# apollo3p register map
Vendor: Ambiq Micro; Series: Apollo; File version: 1.0
CPU: CM4 r1p0, little endian, MPU, FPU, I-cache, D-cache, VTOR, ITCM, DTCM, 3 interrupt priority bits, 0 interrupts
Registers are 32-bit, read-write, reset 0x0 unless marked. A register's access mark holds for its fields unless they carry their own. Offsets are from the block's base; [hi:lo] are bit positions; {n}, {i} and the like mark numbered series; 'fields as' and 'values as' point back to an identical list.

## ADC — Analog Digital Converter Control
Base 0x50010000
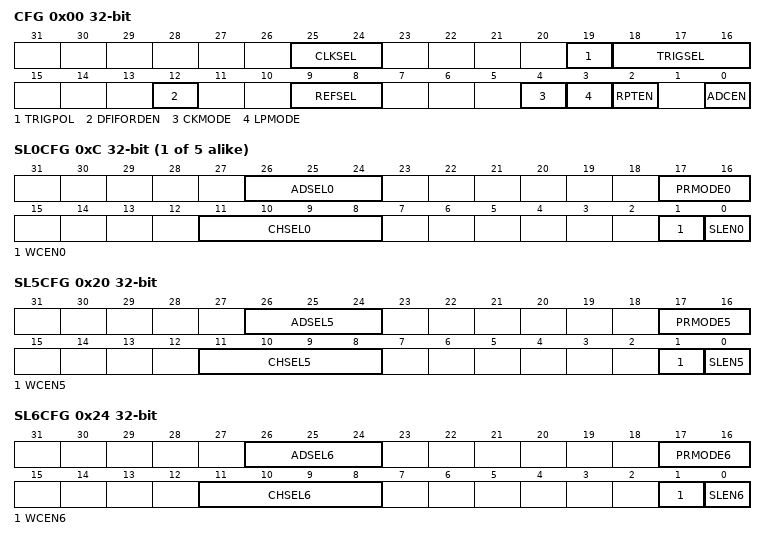
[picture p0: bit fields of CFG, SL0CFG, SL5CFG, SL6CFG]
0x00 CFG — The ADC Configuration Register contains the software control for selecting the clock frequency used for the SAR conversions, the trigger polarity, the trigger select, the reference voltage select, the low power mode, the operating mode (single scan per trigger vs. repeating mode) and ADC enable.
  [25:24] CLKSEL — Select the source and frequency for the ADC clock. All values not enumerated below are undefined.
    0=OFF (Off mode. The HFRC or HFRC_DIV2 clock must be selected for the ADC to function. The ADC controller automatically shuts off the clock in it's low power modes. When setting ADCEN to '0', the CLKSEL should remain set to one of the two clock selects for proper power down sequencing.); 1=HFRC (HFRC Core Clock divided by (CORESEL+1)); 2=HFRC_DIV2 (HFRC Core Clock / 2 further divided by (CORESEL+1))
  [19] TRIGPOL — This bit selects the ADC trigger polarity for external off chip triggers.
    0=RISING_EDGE (Trigger on rising edge.); 1=FALLING_EDGE (Trigger on falling edge.)
  [18:16] TRIGSEL — Select the ADC trigger source.
    {v}=EXT{v} (Off chip External Trigger{v} (ADC_ET{v})) (v=0..3); 4=VCOMP (Voltage Comparator Output); 7=SWT (Software Trigger)
  [12] DFIFORDEN — Destructive FIFO Read Enable. Setting this will enable FIFO pop upon reading the FIFOPR register.
    0=DIS (Destructive Reads are prevented. Reads to the FIFOPR register will not POP an entry off the FIFO.); 1=EN (Reads to the FIFOPR register will automatically pop an entry off the FIFO.)
  [9:8] REFSEL — Select the ADC reference voltage.
    0=INT2P0 (Internal 2.0V Bandgap Reference Voltage); 1=INT1P5 (Internal 1.5V Bandgap Reference Voltage); 2=EXT2P0 (Off Chip 2.0V Reference); 3=EXT1P5 (Off Chip 1.5V Reference)
  [4] CKMODE — Clock mode register
    0=LPCKMODE (Disable the clock between scans for LPMODE0. Set LPCKMODE to 0x1 while configuring the ADC.); 1=LLCKMODE (Low Latency Clock Mode. When set, HFRC and the adc_clk will remain on while in functioning in LPMODE0.)
  [3] LPMODE — Select power mode to enter between active scans.
    0=MODE0 (Low Power Mode 0. Leaves the ADC fully powered between scans with minimum latency between a trigger event and sample data collection.); 1=MODE1 (Low Power Mode 1. Powers down all circuity and clocks associated with the ADC until the next trigger event. Between scans, the reference buffer requires up to 50us of delay from a scan trigger event before the conversion will commence while operating in this mode.)
  [2] RPTEN — This bit enables Repeating Scan Mode.
    0=SINGLE_SCAN (In Single Scan Mode, the ADC will complete a single scan upon each trigger event.); 1=REPEATING_SCAN (In Repeating Scan Mode, the ADC will complete it's first scan upon the initial trigger event and all subsequent scans will occur at regular intervals defined by the configuration programmed for the CTTMRA3 internal timer until the timer is disabled or the ADC is disabled. When disabling the ADC (setting ADCEN to '0'), the RPTEN bit should be cleared.)
  [0] ADCEN — This bit enables the ADC module. While the ADC is enabled, the ADCCFG and SLOT Configuration register settings must remain stable and unchanged. All configuration register settings, slot configuration settings and window comparison settings should be written prior to setting the ADCEN bit to '1'.
    0=DIS (Disable the ADC module.); 1=EN (Enable the ADC module.)
0x04 STAT — This register indicates the basic power status for the ADC. For detailed power status, see the power control power status register. ADC power mode 0 indicates the ADC is in it's full power state and is ready to process scans. ADC Power mode 1 indicates the ADC enabled and in a low power state.
  [0] PWDSTAT — Indicates the power-status of the ADC.
    0=ON (Powered on.); 1=POWERED_DOWN (ADC Low Power Mode 1.)
0x08 SWT — This register enables initiating an ADC scan through software.
  [7:0] SWT — Writing 0x37 to this register generates a software trigger.
    55=GEN_SW_TRIGGER (Writing this value generates a software trigger.)
{0xC+4i} SL{i}CFG (i=0..4) — Slot {i} Configuration Register
  [26:24] ADSEL{i} — Select the number of measurements to average in the accumulate divide module for this slot.
    0=AVG_1_MSRMT (Average in 1 measurement in the accumulate divide module for this slot.); 1=AVG_2_MSRMTS (Average in 2 measurements in the accumulate divide module for this slot.); 2=AVG_4_MSRMTS (Average in 4 measurements in the accumulate divide module for this slot.); 3=AVG_8_MSRMT (Average in 8 measurements in the accumulate divide module for this slot.); 4=AVG_16_MSRMTS (Average in 16 measurements in the accumulate divide module for this slot.); 5=AVG_32_MSRMTS (Average in 32 measurements in the accumulate divide module for this slot.); 6=AVG_64_MSRMTS (Average in 64 measurements in the accumulate divide module for this slot.); 7=AVG_128_MSRMTS (Average in 128 measurements in the accumulate divide module for this slot.)
  [17:16] PRMODE{i} — Set the Precision Mode For Slot.
    0=P14B (14-bit precision mode); 1=P12B (12-bit precision mode); 2=P10B (10-bit precision mode); 3=P8B (8-bit precision mode)
  [11:8] CHSEL{i} — Select one of the 14 channel inputs for this slot.
    0=SE0 (single ended external GPIO connection to pad16.); 1=SE1 (single ended external GPIO connection to pad29.); 2=SE2 (single ended external GPIO connection to pad11.); {v}=SE{v} (single ended external GPIO connection to pad{v+28}.) (v=3..7); 8=SE8 (single ended external GPIO connection to pad13.); 9=SE9 (single ended external GPIO connection to pad12.); 10=DF0 (differential external GPIO connections to pad12(N) and pad13(P).); 11=DF1 (differential external GPIO connections to pad15(N) and pad14(P).); 12=TEMP (internal temperature sensor.); 13=BATT (internal voltage divide-by-3 connection.); 14=VSS (Input VSS)
  [1] WCEN{i} — This bit enables the window compare function for slot {i}.
    1=WCEN (Enable the window compare for slot {i}.)
  [0] SLEN{i} — This bit enables slot {i} for ADC conversions.
    1=SLEN (Enable slot {i} for ADC conversions.)
0x20 SL5CFG — Slot 5 Configuration Register
  [26:24] ADSEL5 — Select number of measurements to average in the accumulate divide module for this slot.
    values as SL0CFG.ADSEL{i}
  [17:16] PRMODE5 — Set the Precision Mode For Slot.
    values as SL0CFG.PRMODE{i}
  [11:8] CHSEL5 — Select one of the 14 channel inputs for this slot.
    values as SL0CFG.CHSEL{i}
  [1] WCEN5 — This bit enables the window compare function for slot 5.
    1=WCEN (Enable the window compare for slot 5.)
  [0] SLEN5 — This bit enables slot 5 for ADC conversions.
    1=SLEN (Enable slot 5 for ADC conversions.)
0x24 SL6CFG — Slot 6 Configuration Register
  [26:24] ADSEL6 — Select the number of measurements to average in the accumulate divide module for this slot.
    values as SL0CFG.ADSEL{i}
  [17:16] PRMODE6 — Set the Precision Mode For Slot.
    values as SL0CFG.PRMODE{i}
  [11:8] CHSEL6 — Select one of the 14 channel inputs for this slot.
    values as SL0CFG.CHSEL{i}
  [1] WCEN6 — This bit enables the window compare function for slot 6.
    1=WCEN (Enable the window compare for slot 6.)
  [0] SLEN6 — This bit enables slot 6 for ADC conversions.
    1=SLEN (Enable slot 6 for ADC conversions.)
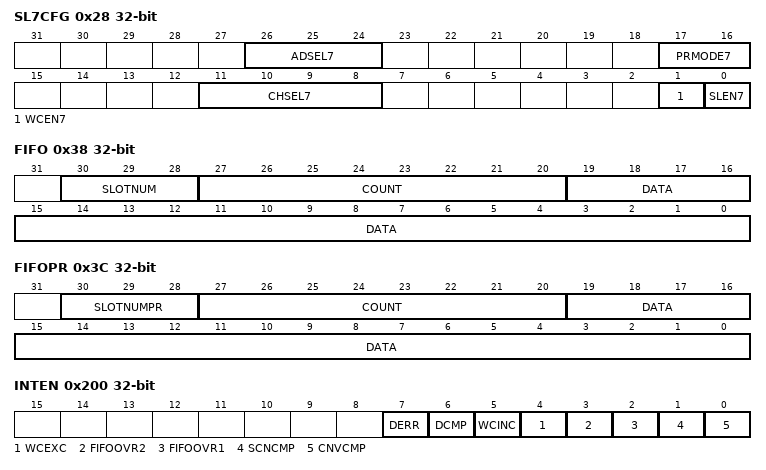
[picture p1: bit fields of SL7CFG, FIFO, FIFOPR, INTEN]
0x28 SL7CFG — Slot 7 Configuration Register
  [26:24] ADSEL7 — Select the number of measurements to average in the accumulate divide module for this slot.
    values as SL0CFG.ADSEL{i}
  [17:16] PRMODE7 — Set the Precision Mode For Slot.
    values as SL0CFG.PRMODE{i}
  [11:8] CHSEL7 — Select one of the 14 channel inputs for this slot.
    values as SL0CFG.CHSEL{i}
  [1] WCEN7 — This bit enables the window compare function for slot 7.
    1=WCEN (Enable the window compare for slot 7.)
  [0] SLEN7 — This bit enables slot 7 for ADC conversions.
    1=SLEN (Enable slot 7 for ADC conversions.)
0x2C WULIM — Window Comparator Upper Limits Register
  [19:0] ULIM — Sets the upper limit for the window comparator.
0x30 WLLIM — Window Comparator Lower Limits Register
  [19:0] LLIM — Sets the lower limit for the window comparator.
0x34 SCWLIM — Scale Window Comparator Limits
  [0] SCWLIMEN — Scale the window limits compare values per precision mode. When set to 0x0 (default), the values in the 20-bit limits registers will compare directly with the FIFO values regardless of the precision mode the slot is configured to. When set to 0x1, the compare values will be divided by the difference in precision bits while performing the window limit comparisons.
0x38 FIFO — The ADC FIFO Register contains the slot number and FIFO data for the oldest conversion data in the FIFO. The COUNT field indicates the total number of valid entries in the FIFO. A write to this register will pop one of the FIFO entries off the FIFO and decrease the COUNT by 1 if the COUNT is greater than zero.
  [30:28] SLOTNUM — Slot number associated with this FIFO data.
  [27:20] COUNT — Number of valid entries in the ADC FIFO.
  [19:0] DATA — Oldest data in the FIFO.
0x3C FIFOPR — This is a Pop Read mirrored copy of the ADCFIFO register with the only difference being that reading this register will result in a simultaneous FIFO POP which is also achieved by writing to the ADCFIFO Register. Note: The DFIFORDEN bit must be set in the CFG register for the the destructive read to be enabled.
  [30:28] SLOTNUMPR — Slot number associated with this FIFO data.
  [27:20] COUNT — Number of valid entries in the ADC FIFO.
  [19:0] DATA — Oldest data in the FIFO.
0x200 INTEN — Set bits in this register to allow this module to generate the corresponding interrupt.
  [7] DERR — DMA Error Condition
    1=DMAERROR (DMA Error Condition Occurred)
  [6] DCMP — DMA Transfer Complete
    1=DMACOMPLETE (DMA Completed a transfer)
  [5] WCINC — Window comparator voltage incursion interrupt.
    1=WCINCINT (Window comparator voltage incursion interrupt.)
  [4] WCEXC — Window comparator voltage excursion interrupt.
    1=WCEXCINT (Window comparator voltage excursion interrupt.)
  [3] FIFOOVR2 — FIFO 100 percent full interrupt.
    1=FIFOFULLINT (FIFO 100 percent full interrupt.)
  [2] FIFOOVR1 — FIFO 75 percent full interrupt.
    1=FIFO75INT (FIFO 75 percent full interrupt.)
  [1] SCNCMP — ADC scan complete interrupt.
    1=SCNCMPINT (ADC scan complete interrupt.)
  [0] CNVCMP — ADC conversion complete interrupt.
    1=CNVCMPINT (ADC conversion complete interrupt.)
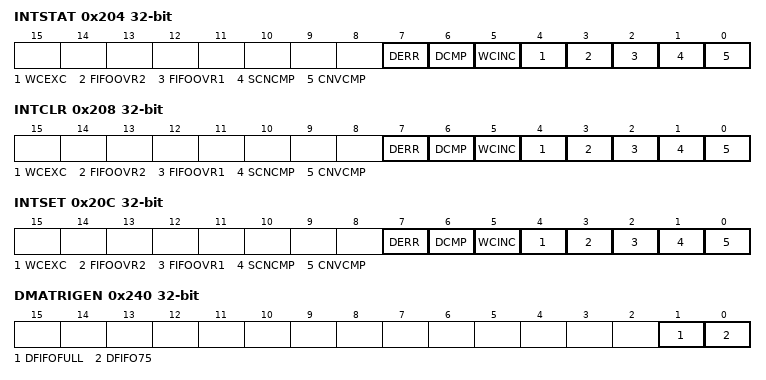
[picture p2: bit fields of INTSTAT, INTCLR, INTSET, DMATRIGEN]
0x204 INTSTAT — Read bits from this register to discover the cause of a recent interrupt.
  fields as INTEN
0x208 INTCLR — Write a 1 to a bit in this register to clear the interrupt status associated with that bit.
  fields as INTEN
0x20C INTSET — Write a 1 to a bit in this register to instantly generate an interrupt from this module. (Generally used for testing purposes).
  fields as INTEN
0x240 DMATRIGEN — DMA Trigger Enable Register
  [1] DFIFOFULL — Trigger DMA upon FIFO 100 percent Full
  [0] DFIFO75 — Trigger DMA upon FIFO 75 percent Full
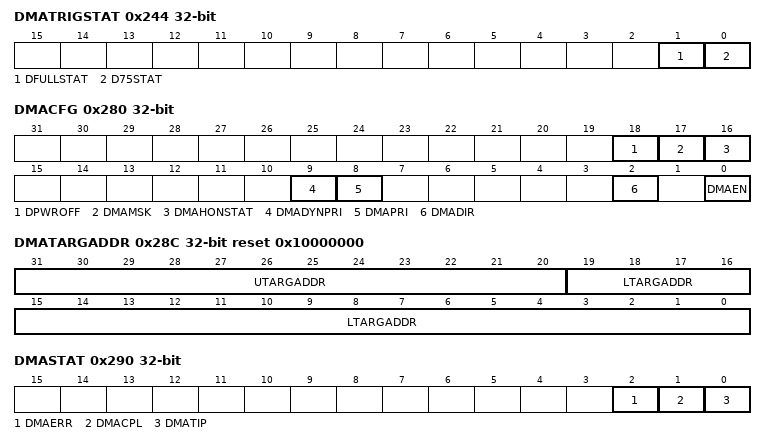
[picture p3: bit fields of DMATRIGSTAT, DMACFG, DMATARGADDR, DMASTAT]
0x244 DMATRIGSTAT — DMA Trigger Status Register
  [1] DFULLSTAT — Triggered DMA from FIFO 100 percent Full
  [0] D75STAT — Triggered DMA from FIFO 75 percent Full
0x280 DMACFG — DMA Configuration Register
  [18] DPWROFF — Power Off the ADC System upon DMACPL.
  [17] DMAMSK — Mask the FIFOCNT and SLOTNUM when transferring FIFO contents to memory
    0=DIS (FIFO Contents are copied directly to memory without modification.); 1=EN (Only the FIFODATA contents are copied to memory on DMA transfers. The SLOTNUM and FIFOCNT contents are cleared to zero.)
  [16] DMAHONSTAT — Halt New ADC conversions until DMA Status DMAERR and DMACPL Cleared.
    0=DIS (ADC conversions will continue regardless of DMA status register); 1=EN (ADC conversions will not progress if DMAERR or DMACPL bits in DMA status register are set.)
  [9] DMADYNPRI — Enables dynamic priority based on FIFO fullness. When FIFO is full, priority is automatically set to HIGH. Otherwise, DMAPRI is used.
    0=DIS (Disable dynamic priority (use DMAPRI setting only)); 1=EN (Enable dynamic priority)
  [8] DMAPRI — Sets the Priority of the DMA request
    0=LOW (Low Priority (service as best effort)); 1=HIGH (High Priority (service immediately))
  [2] DMADIR — Direction
    0=P2M (Peripheral to Memory (SRAM) transaction); 1=M2P (Memory to Peripheral transaction)
  [0] DMAEN — DMA Enable
    0=DIS (Disable DMA Function); 1=EN (Enable DMA Function)
0x288 DMATOTCOUNT — DMA Total Transfer Count
  [17:2] TOTCOUNT — Total Transfer Count
0x28C DMATARGADDR reset 0x10000000 — DMA Target Address Register
  [31:20] UTARGADDR — SRAM Target
  [19:0] LTARGADDR — DMA Target Address
0x290 DMASTAT — DMA Status Register
  [2] DMAERR — DMA Error
  [1] DMACPL — DMA Transfer Complete
  [0] DMATIP — DMA Transfer In Progress
